# TZ10xx register map
File version: 0.1g
Registers are 32-bit, read-write, reset 0x0 unless marked. A register's access mark holds for its fields unless they carry their own. Offsets are from the block's base; [hi:lo] are bit positions; {n}, {i} and the like mark numbered series; <NAME> marks a mode.

## evm
Base 0x40023000
0x00 EVM_EN
  [0] evm_enable — Enable signal for this block 0: Stop 1: Operation
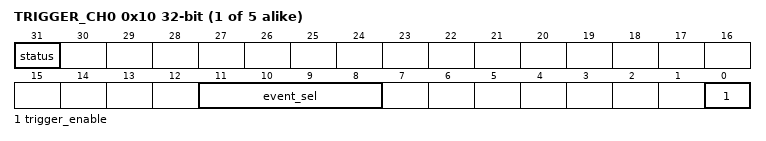
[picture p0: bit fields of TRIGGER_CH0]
{0x10+4i} TRIGGER_CH{i} (i=0..4)
  [31] status ro — Indicates the trigger status. 0: Trigger signal is Low. 1: Trigger signal is High.
  [11:8] event_sel — Event signal selection Writable only when bit0 (trigger enable) is "L". Ignored if written when the bit is "H". 0000: Selects event 0. 0001: Selects event 1. 0010: Selects event 2. 0011: Selects event 3. 0100: Selects event 4. 0101: Selects event 5. 0110: Selects event 6. 0111: Selects event 7. 1000: Selects event 8. 1001: Selects event 9. If the setting is other than the above, the trigger signal is fixed at Low Level.
  [0] trigger_enable — Trigger operation enable signal 0: Stop 1: Operation

## wdt
Base 0x40043000
0x00 WDOGLOAD reset 0xFFFFFFFF — Wdog Watchdog load Register
  [31:0] Load — Value to be loaded to the Wdog counter (min 0x0000_0001) For the 0x00000000 setting, the counter does not operate. Setting other numeric values enable counting.
0x04 WDOGVALUE ro reset 0xFFFFFFFF — Wdog The current value for the watchdog counter Register
  [31:0] Value — Counter value of the Wdog counter at the current time
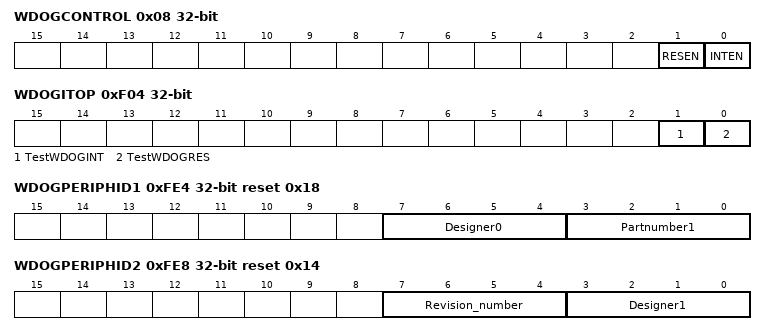
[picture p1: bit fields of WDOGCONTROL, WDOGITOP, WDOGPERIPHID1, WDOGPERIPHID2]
0x08 WDOGCONTROL
  [1] RESEN — WDOGRES output enable 0b1: Enable 0b0: Disable
  [0] INTEN — Wdog interrupt enable 0b1: Enable 0b0: Disable (Note) For the generation timing of WDOGRES and Wdog interrupts, the Wdog interrupt first occurs and then the WDOGRES interrupt occurs when the value of the Wdog counter becomes 0 again with the interrupt not cleared.
0x0C WDOGINTCLR — Wdog Interrupt clear Register
  [31:0] IntClr — Interrupt clear After the Wdog interrupt occurs, it can be cleared by write access to this register.
0x10 WDOGRIS ro — Wdog Raw Interrupt Status Register
  [0] RIS — Wdog interrupt before masking is occurring. 0b1: Interrupt request available 0b0: No interrupt request
0x14 WDOGMIS ro — Wdog Masked Interrupt Status Register
  [0] MIS — Wdog interrupt after masking is occurring. 0b1: Interrupt request available 0b0: No interrupt request
0xC00 WDOGLOCK
  [0] WLOCK — Register writing disable control <Write> If 0x1ACCE551 is written in this register, register writing is enabled. If any value other than 0x1ACCE551 is written, register writing is disabled. <Read> Register writing disable status 0b1: Writing disable 0b0: Writing enable
0xF00 WDOGITCR — Timer Integration test control Register
  [0] ITEN — Test mode control 0b1: Test mode 0b0: Normal operation
0xF04 WDOGITOP — Timer Integration test output set Register
  [1] TestWDOGINT — Outputs the WDOGINT signal (only in test mode, write-only) 0b1: WDOGINT="1" 0b0: WDOGINT="0" If this register is read, the WDT_WDOGITCR value appears.
  [0] TestWDOGRES — Outputs the WDOGRES signal (only in test mode, write-only) 0b1: WDOGRES="1" 0b0: WDOGRES="0" If this register is read, the WDT_WDOGITCR value appears.
0xFE0 WDOGPERIPHID0 ro reset 0x5 — Wdog Peripheral ID0 Register
  [7:0] Partnumber0 — Peripheral ID (this register stores a value from a hardware viewpoint.) Partnumber(Lower) 804=>04
0xFE4 WDOGPERIPHID1 ro reset 0x18 — Wdog Peripheral ID1 Register
  [7:4] Designer0 — Peripheral ID (this register stores a value from a hardware viewpoint.) Designer(Lower) 41=>1
  [3:0] Partnumber1 — Peripheral ID (this register stores a value from a hardware viewpoint.) Partnumber(Lower) 805=>8
0xFE8 WDOGPERIPHID2 ro reset 0x14 — Wdog Peripheral ID2 Register
  [7:4] Revision_number — Peripheral ID (this register stores a value from a hardware viewpoint.) Revision: 1st=>1
  [3:0] Designer1 — Peripheral ID (this register stores a value from a hardware viewpoint.) Designer(Upper) 41=>4
0xFEC WDOGPERIPHID3 ro — Wdog Peripheral ID3 Register
  [7:0] Configuration — Peripheral ID (this register stores a value from a hardware viewpoint.) Configuration: 00
0xFF0 WDOGPCELLID0 ro reset 0xD — Wdog PrimeCell ID0 Register
  [7:0] PCellID0 — Peripheral ID (this register stores a value from a hardware viewpoint.)
0xFF4 WDOGPCELLID1 ro reset 0xF0 — Wdog PrimeCell ID1 Register
  [7:0] PCellID1 — Peripheral ID (this register stores a value from a hardware viewpoint.)
0xFF8 WDOGPCELLID2 ro reset 0x5 — Wdog PrimeCell ID2 Register
  [7:0] PCellID2 — Peripheral ID (this register stores a value from a hardware viewpoint.)
0xFFC WDOGPCELLID3 ro reset 0xB1 — Wdog PrimeCell ID3 Register
  [7:0] PCellID3 — Peripheral ID (this register stores a value from a hardware viewpoint.)

## fpu — Floating Point system registers
Base 0xE000EF34
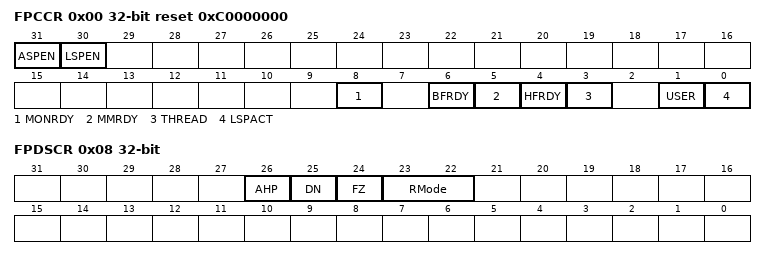
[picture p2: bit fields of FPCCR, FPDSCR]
0x00 FPCCR reset 0xC0000000 — FP Context Control Register
  [31] ASPEN — Enables CONTROL<2> setting on execution of a floating-point instruction. This results in automatic hardware state preservation and restoration, for floating-point context, on exception entry and exit. 0 = Disable CONTROL<2> setting on execution of a floating-point instruction. 1 = Enable CONTROL<2> setting on execution of a floating-point instruction.
  [30] LSPEN — 0 = Disable automatic lazy state preservation for floating-point context. 1 = Enable automatic lazy state preservation for floating-point context.
  [8] MONRDY — 0 = DebugMonitor is disabled or priority did not permit setting MON_PEND when the floating-point stack frame was allocated. 1 = DebugMonitor is enabled and priority permits setting MON_PEND when the floating-point stack frame was allocated.
  [6] BFRDY — 0 = BusFault is disabled or priority did not permit setting the BusFault handler to the pending state when the floating-point stack frame was allocated. 1 = BusFault is enabled and priority permitted setting the BusFault handler to the pending state when the floating-point stack frame was allocated.
  [5] MMRDY — 0 = MemManage is disabled or priority did not permit setting the MemManage handler to the pending state when the floating-point stack frame was allocated. 1 = MemManage is enabled and priority permitted setting the MemManage handler to the pending state when the floating-point stack frame was allocated.
  [4] HFRDY — 0 = Priority did not permit setting the HardFault handler to the pending state when the floating-point stack frame was allocated. 1 = Priority permitted setting the HardFault handler to the pending state when the floating-point stack frame was allocated.
  [3] THREAD — 0 = Mode was not Thread Mode when the floating-point stack frame was allocated. 1 = Mode was Thread Mode when the floating-point stack frame was allocated.
  [1] USER — 0 = Privilege level was not user when the floating-point stack frame was allocated. 1 = Privilege level was user when the floating-point stack frame was allocated.
  [0] LSPACT — 0 = Lazy state preservation is not active. 1 = Lazy state preservation is active. floating-point stack frame has been allocated but saving state to it has been deferred.
0x04 FPCAR — FP Context Address Register
  [31:3] ADDRESS — The location of the unpopulated floating-point register space allocated on an exception stack frame.
0x08 FPDSCR — FP Default Status Control Register
  [26] AHP — Default value for FPSCR.AHP
  [25] DN — Default value for FPSCR.DN
  [24] FZ — Default value for FPSCR.FZ
  [23:22] RMode — Default value for FPSCR.RMode
0x0C MVFR0 ro reset 0x10110021 — Media and VFP Feature Register 0
0x10 MVFR1 ro reset 0x11000011 — Media and VFP Feature Register 1
